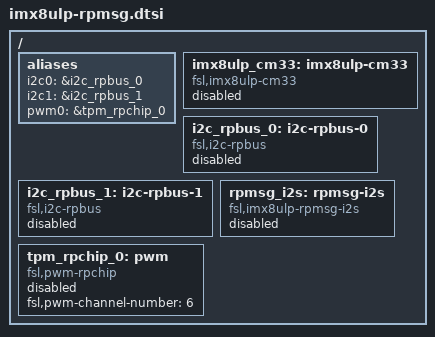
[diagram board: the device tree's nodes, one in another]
// SPDX-License-Identifier: (GPL-2.0+ OR MIT)
/*
 * Copyright 2021 NXP
 */

/ {
	aliases {
		i2c0 = &i2c_rpbus_0;
		i2c1 = &i2c_rpbus_1;
		pwm0 = &tpm_rpchip_0;
	};

	imx8ulp_cm33: imx8ulp-cm33 {
		compatible = "fsl,imx8ulp-cm33", "fsl,imx7ulp-cm4";
		status = "disabled";
	};

	i2c_rpbus_0: i2c-rpbus-0 {
		compatible = "fsl,i2c-rpbus";
		status = "disabled";
	};

	i2c_rpbus_1: i2c-rpbus-1 {
		compatible = "fsl,i2c-rpbus";
		status = "disabled";
	};

	rpmsg_i2s: rpmsg-i2s {
		compatible = "fsl,imx8ulp-rpmsg-i2s";
		status = "disabled";
	};

	tpm_rpchip_0: pwm {
		compatible = "fsl,pwm-rpchip";
		#pwm-cells = <3>;
		fsl,pwm-channel-number = <6>;
		status = "disabled";
	};
};
